# SIBG301M104LGL register map
Vendor: Silicon Labs; Series: Si; File version: B
Registers are 32-bit, read-write, reset 0x0 unless marked. A register's access mark holds for its fields unless they carry their own. Offsets are from the block's base; [hi:lo] are bit positions; lines under a group give offsets from that group; {n}, {i} and the like mark numbered series; 'fields as' and 'values as' point back to an identical list.

## ADC0_NS — ADC0_NS Registers
Base 0x40004000
Same registers: ADC0_S 0x50004000
0x00 IPVERSION ro reset 0x1
  [31:0] IPVERSION — IP version ID
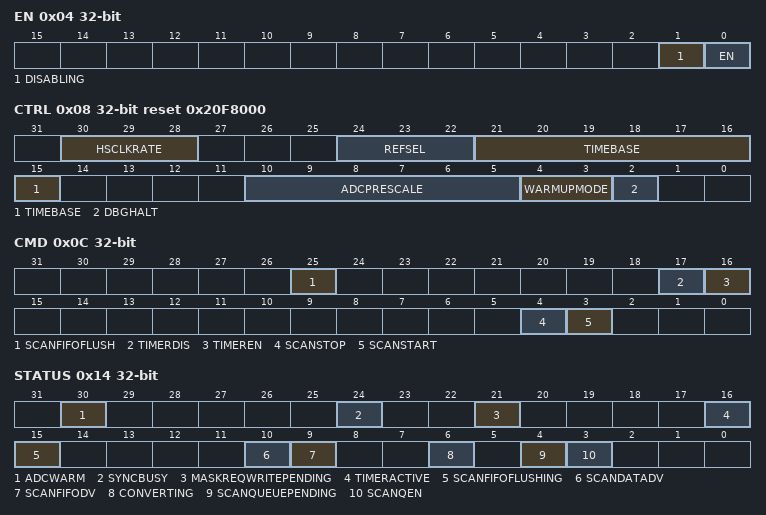
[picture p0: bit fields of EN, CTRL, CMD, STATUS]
0x04 EN — Enable
  [1] DISABLING ro — Disablement busy status
  [0] EN — Enable SAR Module
    0=DISABLE; 1=ENABLE
0x08 CTRL reset 0x20F8000 — Control
  [30:28] HSCLKRATE — High Speed Prescaler
    0=DIV1 (Use clk_per directly.); 1=DIV2 (Divide clk_per by 2 before using it.); {v}=DIV{v+1} (Divide clk_per by {v+1} before using it. the resulting clk_src_adc must be 40Mhz or less) (v=2..7)
  [24:22] REFSEL — Reference Selection
    0=VREFINT (Internal voltage reference); 1=VREFPL (External reference pin low voltage (1.05-1.25)); 2=VREFPH (External reference pin high voltage( >1.25)); 3=VDDA (Analog voltage supply); 4=VREFPBUF (External reference pin buffered)
  [21:15] TIMEBASE
  [10:5] ADCPRESCALE — Second Prescaler
  [4:3] WARMUPMODE
    0=NORMAL (Shut down the analog ADC after conversions have completed. Requires 5 us warmup time on first conversion of any new scan.); 1=KEEPWARM (Keep ADC fully powered after conversions have completed.); 2=KEEPSTANDBY (Keep ADC in low-power standby state after conversions have completed. Requires 1 us warmup time on first converion of any new scan.)
  [2] DBGHALT — Debug Halt
    0=NORMAL (Continue operation as normal during debug mode); 1=HALT (Complete the current conversion and then halt during debug mode)
0x0C CMD wo — Command
  [25] SCANFIFOFLUSH — Flush Scan FIFO
  [17] TIMERDIS — Timer Disable
  [16] TIMEREN — Timer Enable
  [4] SCANSTOP — Scan Queue Stop
  [3] SCANSTART — Scan Queue Start
0x10 TIMER
  [15:0] TIMER — Timer Period
0x14 STATUS ro
  [30] ADCWARM — ADC Warmed Up
  [24] SYNCBUSY — Synchronization in Progress
  [21] MASKREQWRITEPENDING
  [16] TIMERACTIVE
  [15] SCANFIFOFLUSHING — Scan FIFO Flush in Progress
  [10] SCANDATADV — SCANDATA Data Valid
  [9] SCANFIFODV — Scan FIFO Data Valid
  [6] CONVERTING — Ongoing Conversion
  [4] SCANQUEUEPENDING
  [3] SCANQEN — Scan Queued Enabled
0x18 MASKREQ — input mask
  [15:0] MASKREQ — Channel Mask Request
0x1C STMASK ro — scan table mask req
  [15:0] STMASK — Scan Table Mask
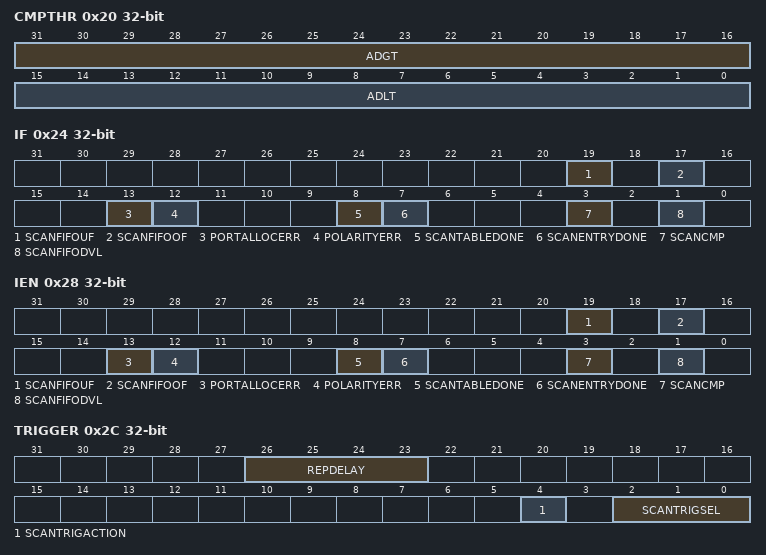
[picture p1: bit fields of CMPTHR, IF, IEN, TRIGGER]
0x20 CMPTHR — Comparator Threshold
  [31:16] ADGT — ADC Greater Than or Equal to Threshold
  [15:0] ADLT — ADC Less Than or Equal to Threshold
0x24 IF — Interrupt Flag
  [19] SCANFIFOUF — Scan FIFO Underflow
  [17] SCANFIFOOF — Scan FIFO Overflow
  [13] PORTALLOCERR — Port Allocation Error
  [12] POLARITYERR — Polarity Error
  [8] SCANTABLEDONE — Scan Sequence Done
  [7] SCANENTRYDONE
  [3] SCANCMP — Scan Result Window Compare
  [1] SCANFIFODVL — Scan FIFO Data Valid Level
0x28 IEN — Interrupt Enable
  [19] SCANFIFOUF — Scan FIFO Underflow Enable
  [17] SCANFIFOOF — Scan FIFO Overflow Enable
  [13] PORTALLOCERR — Port Allocation Error Enable
  [12] POLARITYERR — Polarity Error Enable
  [8] SCANTABLEDONE — Scan Sequence Done
  [7] SCANENTRYDONE
  [3] SCANCMP — Scan Result Window Compare Enable
  [1] SCANFIFODVL — Scan FIFO Data Valid Level Enable
0x2C TRIGGER — trigger settings
  [26:23] REPDELAY — delay between repetitions
    0=NODELAY; 1=CYCLE2 (2 conversion clock cycles); 2=CYCLE4 (4 conversion clock cycles); 3=CYCLE8 (8 conversion clock cycles); 4=CYCLE16 (16 conversion clock cycles); 5=CYCLE32 (32 conversion clock cycles); 6=CYCLE64 (64 conversion clock cycles); 7=CYCLE128 (128 conversion clock cycles); 8=CYCLE256 (256 conversion clock cycles); 9=CYCLE512 (512 conversion clock cycles); 10=CYCLE1024 (1024 conversion clock cycles)
  [4] SCANTRIGACTION — Scan trigger action
    0=ONCE (Goes through scan table once per trigger); 1=CONTINUOUS (goes through the scan table converts every entry in maskbit and keeps going through the table until stop command is issued or module is diabled)
  [2:0] SCANTRIGSEL — Scan Trigger Select
    0=IMMEDIATE (Immediate triggering. The scan queue will be disabled once all conversions in the scan table are complete, unless TRIGGERACTION is set to continuous.); 1=TIMER (Triggers when the local timer count reaches zero.); 2=PRSCLKGRP (Triggers on PRS0 from a timer module that is using the same clock group as the ADC and has been programmed to use the same clock source as the ADC. The prescale may be different between the ADC and the timer module.); 3=PRSPOS (Triggers on asynchronous PRS0 positive edge. Requires PRS0 to go low for 3 ADCCLKs before another positive edge can be detected. Generates an additional delay of 1 to 2 CLK_SRC_ADC cycles for synchronization.); 4=PRSNEG (Triggers on asynchronous PRS0 negative edge. Requires PRS0 to go high for 3 ADCCLKs before another negative edge can be detected. Generates an additional delay of 1 to 2 CLK_SRC_ADC cycles for synchronization. PRSNEG should only be used when the PRS trigger source is from a module on a PD0 or PDHV power domain. For modules (ie: TIMER) on a PD1 power domain, PRSPOS should be used for an asynchronous trigger, and PRSCLKGRP should be used for a synchronous trigger.)
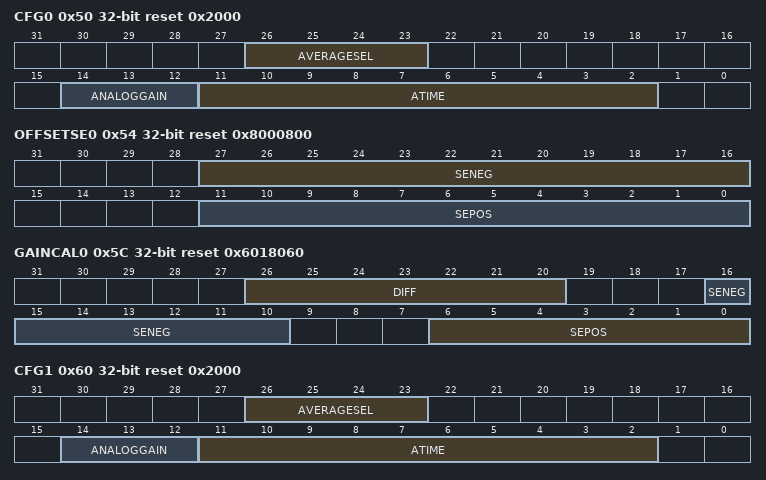
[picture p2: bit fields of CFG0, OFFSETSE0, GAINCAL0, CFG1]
0x50 CFG0 reset 0x2000 — Configuration register
  [26:23] AVERAGESEL — Average Select
    0=1 samples for each conversion result; 1=X2 (2 samples for each conversion result); 2=X4 (4 samples for each conversion result); 3=X8 (8 samples for each conversion result); 4=X16 (16 samples for each conversion result); 5=X32 (32 samples for each conversion result); 6=X64 (64 samples for each conversion result); 7=X128 (128 samples for each conversion result); 8=X256 (256 samples for each conversion result); 9=X512 (512 samples for each conversion result); 10=X1024 (1024 samples for each conversion result)
  [14:12] ANALOGGAIN
    0=GAIN_0_3125 (Gain for sampling cap of 0.3125x); 1=GAIN_0_5 (Gain for sampling cap of 0.5x); 2=GAIN_1 (Gain for sampling cap of 1x); 3=GAIN_2 (Gain for sampling cap of 2x); 4=GAIN_4 (Gain for sampling cap of 4x)
  [11:2] ATIME — Acquisition Time
0x54 OFFSETSE0 reset 0x8000800 — offset trimming
  [27:16] SENEG — Offset Trim Single Ended Negative
  [11:0] SEPOS — Offset Trim Single Ended Positive
0x58 OFFSETDIFF0 reset 0x800 — trimming value for differential mode
  [11:0] DIFF — Offset Trim Differential
0x5C GAINCAL0 reset 0x6018060 — gain calibration
  [26:20] DIFF — Gain Calibration for Differential
  [16:10] SENEG — Gain Calibration for Single Ended Negative
  [6:0] SEPOS — Gain Calibration for Single Ended Positive
0x60 CFG1 reset 0x2000 — Configuration register
  fields as CFG0
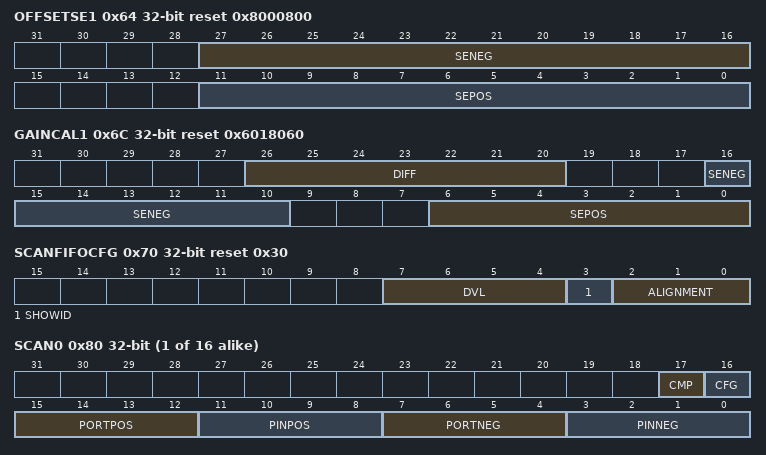
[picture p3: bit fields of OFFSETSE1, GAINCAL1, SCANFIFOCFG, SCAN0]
0x64 OFFSETSE1 reset 0x8000800 — offset trimming
  fields as OFFSETSE0
0x68 OFFSETDIFF1 reset 0x800 — trimming value for differential mode
  [11:0] DIFF — Offset Trim Differential
0x6C GAINCAL1 reset 0x6018060 — gain calibration
  fields as GAINCAL0
0x70 SCANFIFOCFG reset 0x30 — SCAN FIFO configuration
  [7:4] DVL — Data Valid Level
    0=VALID1 (When 1 entry in the scan FIFO is valid, set the SCANFIFODVL interrupt and request DMA.); {v}=VALID{v+1} (When {v+1} entries in the scan FIFO are valid, set the SCANFIFODVL interrupt and request DMA.) (v=1..15)
  [3] SHOWID
  [2:0] ALIGNMENT
    0=RIGHT16 (ID[7:0], SIGN_EXT, DATA[15:0]); 1=RIGHT12 (ID[7:0], SIGN_EXT, DATA[11:0]); 2=RIGHT8 (ID[7:0], SIGN_EXT, DATA[7:0]); 3=LEFT16 (DATA[15:0], 00000000, ID[7:0]); 4=LEFT12 (DATA[11:0], 000000000000, ID[7:0]); 5=LEFT8 (DATA[7:0], 0000000000000000, ID[7:0])
0x74 SCANFIFODATA ro — Read the oldest valid data from the scan FIFO and pop the FIFO
  [31:0] DATA
0x78 SCANFIFOSTAT ro — Scan FIFO status
  [4:0] FIFOREADCNT — FIFO Read Count
0x7C SCANDATA ro — Most recent data data from scan queue conversion
  [31:0] DATA
{0x80+4i} SCAN{i} (i=0..15)
  [17] CMP — Comparison Enable
  [16] CFG — Configuration Group Select
    0=CONFIG0 (Use configuration group 0); 1=CONFIG1 (Use configuration group 1)
  [15:12] PORTPOS — Positive Port Select
    0=GND (Ground); 1=SUPPLY (Supply Pin - Select specific supply using PINPOS); 8=PORTA (Port A - Select pin number using PINPOS); 9=PORTB (Port B - Select pin number using PINPOS); 10=PORTC (Port C - Select pin number using PINPOS); 11=PORTD (Port D - Select pin number using PINPOS)
  [11:8] PINPOS — Positive Pin Select
  [7:4] PORTNEG — Negative Port Select
    0=GND (Ground (single-ended)); 8=PORTA (Port A - Select pin number using PINNEG); 9=PORTB (Port B - Select pin number using PINNEG); 10=PORTC (Port C - Select pin number using PINNEG); 11=PORTD (Port D - Select pin number using PINNEG)
  [3:0] PINNEG — Negative Pin Select
